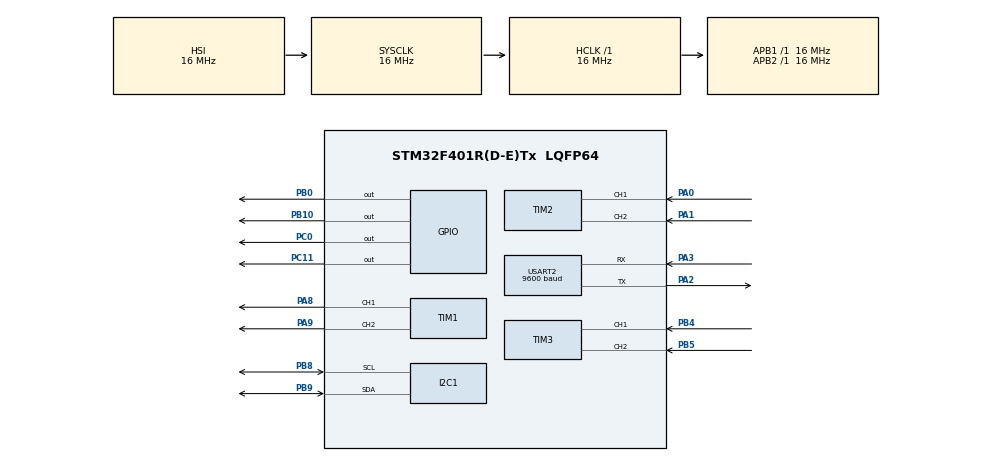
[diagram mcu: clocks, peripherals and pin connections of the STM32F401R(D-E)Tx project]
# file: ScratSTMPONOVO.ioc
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I2C1.I2C_Mode=I2C_Fast
Mcu.Family=STM32F4
Mcu.Name=STM32F401R(D-E)Tx
Mcu.Package=LQFP64
NVIC.PriorityGroup=NVIC_PRIORITYGROUP_4
PA0-WKUP.Signal=S_TIM2_CH1_ETR
PA1.Signal=S_TIM2_CH2
PA2.Mode=Asynchronous
PA2.Signal=USART2_TX
PA3.Mode=Asynchronous
PA3.Signal=USART2_RX
PA8.Signal=S_TIM1_CH1
PA9.Signal=S_TIM1_CH2
PB0.Signal=GPIO_Output
PB10.Signal=GPIO_Output
PB4.Signal=S_TIM3_CH1
PB5.Signal=S_TIM3_CH2
PB8.Mode=I2C
PB8.Signal=I2C1_SCL
PB9.Mode=I2C
PB9.Signal=I2C1_SDA
PC0.Signal=GPIO_Output
PC11.Signal=GPIO_Output
ProjectManager.HeapSize=0x200
ProjectManager.StackSize=0x400
ProjectManager.TargetToolchain=STM32CubeIDE
RCC.AHBFreq_Value=16000000
RCC.APB1Freq_Value=16000000
RCC.APB2Freq_Value=16000000
RCC.CortexFreq_Value=16000000
RCC.HSE_VALUE=25000000
RCC.HSI_VALUE=16000000
RCC.LSE_VALUE=32768
RCC.SYSCLKFreq_VALUE=16000000
RCC.VCOOutputFreq_Value=192000000
SH.S_TIM1_CH1.0=TIM1_CH1,PWM Generation1 CH1
SH.S_TIM1_CH2.0=TIM1_CH2,PWM Generation2 CH2
SH.S_TIM2_CH1_ETR.0=TIM2_CH1,Encoder_Interface
SH.S_TIM2_CH2.0=TIM2_CH2,Encoder_Interface
SH.S_TIM3_CH1.0=TIM3_CH1,Encoder_Interface
SH.S_TIM3_CH2.0=TIM3_CH2,Encoder_Interface
TIM1.Channel-PWM\ Generation1\ CH1=TIM_CHANNEL_1
TIM1.Channel-PWM\ Generation2\ CH2=TIM_CHANNEL_2
USART2.BaudRate=9600
USART2.VirtualMode=VM_ASYNC
board=custom

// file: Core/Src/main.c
/* USER CODE BEGIN Header */
/**
  ******************************************************************************
  * @file           : main.c
  * @brief          : Main program body
  ******************************************************************************
  * @attention
  *
  * <h2><center>&copy; Copyright (c) 2026 STMicroelectronics.
  * All rights reserved.</center></h2>
  *
  * This software component is licensed by ST under BSD 3-Clause license,
  * the "License"; You may not use this file except in compliance with the
  * License. You may obtain a copy of the License at:
  *                        opensource.org/licenses/BSD-3-Clause
  *
  ******************************************************************************
  */
/* USER CODE END Header */

#include "main.h"
#include "i2c.h"
#include "tim.h"
#include "usart.h"
#include "gpio.h"
#include "../../Core/Lib/TCS34725/TCS34725.h"
#include "uartKomunikacija.h"
#include <stdio.h>

/* USER CODE BEGIN PV */
uint8_t text[100] = "RGB Vrednosti su: ";
uint16_t r_raw, g_raw, b_raw, c_raw;
int red, green, blue, color;

/* USER CODE END PV */

void SystemClock_Config(void);

int main(void)
{

  /* MCU Configuration--------------------------------------------------------*/

  /* Reset of all peripherals, Initializes the Flash interface and the Systick. */
  HAL_Init();

  /* Configure the system clock */
  SystemClock_Config();

  /* Initialize all configured peripherals */
  MX_GPIO_Init();
  MX_I2C1_Init();
  MX_TIM1_Init();
  MX_TIM2_Init();
  MX_TIM3_Init();
  MX_USART2_UART_Init();
  /* USER CODE BEGIN 2 */
  	GPIOInterruptInit();
    GPIOInit();
  /* USER CODE END 2 */

  /* Infinite loop */
  while (1)
  {

    /* USER CODE BEGIN 3 */
	  getRawData(&r_raw, &g_raw, &b_raw, &c_raw);
	  getRGB(&red, &green, &blue);
	  snprintf(text, sizeof(text),
	           " R=%d  G=%d  B=%d\r\n",
	           red, green, blue);
	  uartx_write_text(&huart2, text);
	  HAL_Delay(1000);
  }
  /* USER CODE END 3 */
}

void SystemClock_Config(void)
{
  RCC_OscInitTypeDef RCC_OscInitStruct = {0};
  RCC_ClkInitTypeDef RCC_ClkInitStruct = {0};

  /** Configure the main internal regulator output voltage
  */
  __HAL_RCC_PWR_CLK_ENABLE();
  __HAL_PWR_VOLTAGESCALING_CONFIG(PWR_REGULATOR_VOLTAGE_SCALE2);
  /** Initializes the CPU, AHB and APB busses clocks
  */
  RCC_OscInitStruct.OscillatorType = RCC_OSCILLATORTYPE_HSI;
  RCC_OscInitStruct.HSIState = RCC_HSI_ON;
  RCC_OscInitStruct.HSICalibrationValue = RCC_HSICALIBRATION_DEFAULT;
  RCC_OscInitStruct.PLL.PLLState = RCC_PLL_NONE;
  if (HAL_RCC_OscConfig(&RCC_OscInitStruct) != HAL_OK)
  {
    Error_Handler();
  }
  /** Initializes the CPU, AHB and APB busses clocks
  */
  RCC_ClkInitStruct.ClockType = RCC_CLOCKTYPE_HCLK|RCC_CLOCKTYPE_SYSCLK
                              |RCC_CLOCKTYPE_PCLK1|RCC_CLOCKTYPE_PCLK2;
  RCC_ClkInitStruct.SYSCLKSource = RCC_SYSCLKSOURCE_HSI;
  RCC_ClkInitStruct.AHBCLKDivider = RCC_SYSCLK_DIV1;
  RCC_ClkInitStruct.APB1CLKDivider = RCC_HCLK_DIV1;
  RCC_ClkInitStruct.APB2CLKDivider = RCC_HCLK_DIV1;

  if (HAL_RCC_ClockConfig(&RCC_ClkInitStruct, FLASH_LATENCY_0) != HAL_OK)
  {
    Error_Handler();
  }
}

void Error_Handler(void)
{
}

/************************ (C) COPYRIGHT STMicroelectronics *****END OF FILE****/
